# axidma register map
File version: 7.1
axidma device descript
Registers are 32-bit, read-write, reset 0x0 unless marked. A register's access mark holds for its fields unless they carry their own. Offsets are from the block's base; lines under a group give offsets from that group; [hi:lo] are bit positions; {n}, {i} and the like mark numbered series; 'fields as' and 'values as' point back to an identical list; <NAME> marks a mode.

## Memory map
0x00000000 SG_DESC — Scatter Gather Descriptor
0x00000000 CHANNEL — The Registers of channel
0x60100000 AXI_DMA size 0x10000 — AXI Direct Memory Access

## SG_DESC — Scatter Gather Descriptor
Base 0x00000000
0x00 nxt_desc — Next Descriptor Pointer
  [31:6] nxt_desc_ptr — Indicates the lower order pointer pointing to the first word of the next descriptor
0x04 nxt_desc_msb — Upper 32 bits of Next Descriptor Pointer
  [31:0] nxt_desc_ptr — Indicates the MSB 32 bits of the pointer pointing to the first word of the next descriptor
0x08 buf_addr — Buffer Address
  [31:0] buf_addr — Provides the location of the data to transfer.
0x0C buf_addr_msb — Upper 32 bits of Buffer Address
  [31:0] buf_addr — Provides the MSB 32 bits of the location of the data to transfer.
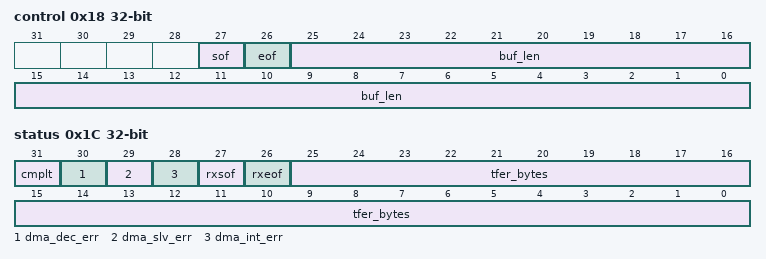
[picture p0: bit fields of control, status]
0x18 control — Control of BD
  [27] sof — Start of Frame. Flag indicating the first buffer to be processed.
    0=FALSE; 1=TRUE
  [26] eof — End of Frame. Flag indicating the last buffer to be processed.
    0=FALSE; 1=TRUE
  [25:0] buf_len — Indicates the amount of space in bytes of the stream.
0x1C status ro — Status of BD
  [31] cmplt — Completed. This indicates to the software that the DMA Engine has completed the transfer as described by the associated descriptor.
    0=FALSE; 1=TRUE
  [30] dma_dec_err — DMA Decode Error. Decode Error detected by primary AXI DataMover. This error occurs if the Descriptor Buffer Address points to an invalid address.
    0=NO_ERR; 1=DETECTED
  [29] dma_slv_err — DMA Slave Error. Slave Error detected by primary AXI DataMover. This error occurs if the slave read from the Memory Map interface issues a Slave Error.
    0=NO_ERR; 1=DETECTED
  [28] dma_int_err — DMA Internal Error. Internal Error detected by primary AXI DataMover. This error can occur if a 0 length bytes to transfer is fed to the AXI DataMover.
    0=NO_ERR; 1=DETECTED
  [27] rxsof — Start of Frame. Flag indicating buffer holds first part of packet. This bit is set by AXI DMA to indicate to the sw/user that the buffer associated with this descriptor contains the start of the packet.
    0=FALSE; 1=TRUE
  [26] rxeof — End of Frame. Flag indicating buffer holds the last part of packet. This bit is set by AXI DMA to indicate to the sw/user that the buffer associated with this descriptor contains the end of the packet.
    0=FALSE; 1=TRUE
  [25:0] tfer_bytes — This value indicates the amount of data received and stored in the buffer described by this descriptor. This might or might not match the buffer length.
{0x20+4i} app[{i}] (i=0..4) — User Application Field [{i}]
  [31:0] app — Specifies user-specific application data.

## CHANNEL — The Registers of channel
Base 0x00000000
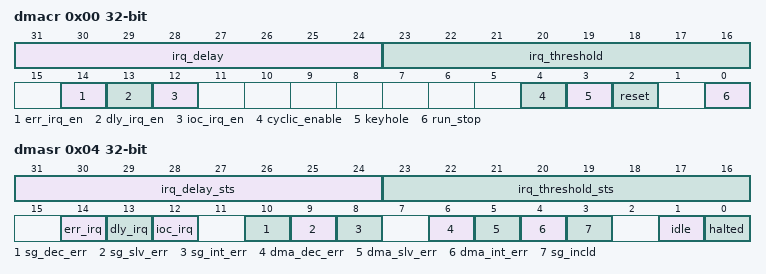
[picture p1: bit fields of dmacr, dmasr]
0x00 dmacr — DMA Channel Control register
  [31:24] irq_delay — Interrupt Delay Time Out
  [23:16] irq_threshold — Interrupt Threshold
  [14] err_irq_en — Interrupt on Error Interrupt Enable
    0=DISABLE; 1=ENABLE
  [13] dly_irq_en — Interrupt on Delay Timer Interrupt Enable
    0=DISABLE; 1=ENABLE
  [12] ioc_irq_en — Interrupt on Complete (IOC) Interrupt Enable
    0=DISABLE; 1=ENABLE
  [4] cyclic_enable — When set to 1, the DMA operates in Cyclic Buffer Descriptor (BD) mode without any user intervention
    0=DISABLE; 1=ENABLE
  [3] keyhole — Keyhole Read
    0=DISABLE; 1=ENABLE
  [2] reset — Soft reset for resetting the AXI DMA core
    0=NORMAL; 1=RESET
  [0] run_stop — Run / Stop control for controlling running and stopping of the DMA channel.
    0=STOP; 1=RUN
0x04 dmasr — DMA Channel Status register
  [31:24] irq_delay_sts — Interrupt Delay Time Status. Indicates current interrupt delay time value.
  [23:16] irq_threshold_sts — Interrupt Threshold Status. Indicates current interrupt threshold value.
  [14] err_irq — Interrupt on Error
    0=NO_INTR; 1=DETECTED
  [13] dly_irq — Interrupt on Delay Timer
    0=NO_INTR; 1=DETECTED
  [12] ioc_irq — Interrupt on Complete (IOC)
    0=NO_INTR; 1=DETECTED
  [10] sg_dec_err — Scatter Gather Decode Error. This error occurs if CURDESC_PTR and/or NXTDESC_PTR points to an invalid address.
    0=NO_ERR; 1=DETECTED
  [9] sg_slv_err — Scatter Gather Slave Error. This error occurs if the slave read from on the Memory Map interface issues a Slave error.
    0=NO_ERR; 1=DETECTED
  [8] sg_int_err — Scatter Gather Internal Error. This error occurs if a descriptor with the “Complete bit” already set is fetched.
    0=NO_ERR; 1=DETECTED
  [6] dma_dec_err — DMA Decode Error. This error occurs if the address request points to an invalid address.
    0=NO_ERR; 1=DETECTED
  [5] dma_slv_err — DMA Slave Error. This error occurs if the slave read from the Memory Map interface issues a Slave Error.
    0=NO_ERR; 1=DETECTED
  [4] dma_int_err — DMA Internal Error. Internal error occurs if the buffer length specified in the fetched descriptor is set to 0.
    0=NO_ERR; 1=DETECTED
  [3] sg_incld — Scatter Gather Engine Included. DMASR.SGIncld = 1 indicates the Scatter Gather engine is included and the AXI DMA is configured for Scatter Gather mode.
    0=SG_DISABLED; 1=SG_ENABLED
  [1] idle — DMA Channel Idle. Indicates the state of AXI DMA operations.
    0=NOT_IDLE; 1=IDLE
  [0] halted — DMA Channel Halted. Indicates the run/stop state of the DMA channel.
    0=RUNNING; 1=HALTED
0x08 curdesc — Current Descriptor Pointer. Lower 32 bits of the address.
  [31:6] curdesc_ptr — Indicates the pointer of the current descriptor being worked on.
0x0C curdesc_msb — Current Descriptor Pointer. Upper 32 bits of the address.
  [31:0] curdesc_ptr — Indicates the pointer of the current descriptor being worked on.
0x10 taildesc — Tail Descriptor Pointer. Lower 32 bits of the address.
  [31:6] taildesc_ptr — Indicates the pause pointer in a descriptor chain.
0x14 taildesc_msb — Tail Descriptor Pointer. Upper 32 bits of the address.
  [31:0] taildesc_ptr — Indicates the pause pointer in a descriptor chain.
